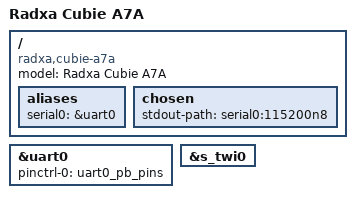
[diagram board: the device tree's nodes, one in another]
// SPDX-License-Identifier: (GPL-2.0-only OR MIT)
// Copyright (C) 2026 Jerome Brunet <jbrunet@baylibre.com>

/dts-v1/;

#include "sun60i-a733.dtsi"

/ {
	model = "Radxa Cubie A7A";
	compatible = "radxa,cubie-a7a", "allwinner,sun60i-a733";

	aliases {
		serial0 = &uart0;
	};

	chosen {
		stdout-path = "serial0:115200n8";
	};
};

&uart0 {
	pinctrl-names = "default";
	pinctrl-0 = <&uart0_pb_pins>;
	status = "okay";
};

&s_twi0 {
	status = "okay";
};
